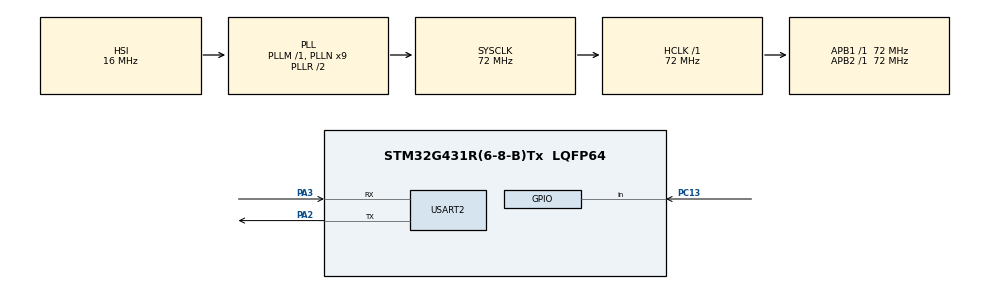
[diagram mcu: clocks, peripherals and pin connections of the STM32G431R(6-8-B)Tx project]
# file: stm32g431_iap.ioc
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IWDG.Prescaler=IWDG_PRESCALER_256
Mcu.Family=STM32G4
Mcu.Name=STM32G431R(6-8-B)Tx
Mcu.Package=LQFP64
NVIC.PriorityGroup=NVIC_PRIORITYGROUP_4
PA2.Mode=Asynchronous
PA2.Signal=USART2_TX
PA3.Mode=Asynchronous
PA3.Signal=USART2_RX
PC13.Signal=GPIO_Input
ProjectManager.HeapSize=0x400
ProjectManager.StackSize=0x800
ProjectManager.TargetToolchain=MDK-ARM V5
RCC.ADC12Freq_Value=72000000
RCC.AHBFreq_Value=72000000
RCC.APB1Freq_Value=72000000
RCC.APB1TimFreq_Value=72000000
RCC.APB2Freq_Value=72000000
RCC.APB2TimFreq_Value=72000000
RCC.CortexFreq_Value=72000000
RCC.EXTERNAL_CLOCK_VALUE=12288000
RCC.HCLKFreq_Value=72000000
RCC.HSE_VALUE=24000000
RCC.HSI48_VALUE=48000000
RCC.HSI_VALUE=16000000
RCC.LSE_VALUE=32768
RCC.PLLN=9
RCC.SYSCLKFreq_VALUE=72000000
RCC.SYSCLKSource=RCC_SYSCLKSOURCE_PLLCLK
RCC.USBFreq_Value=72000000
RCC.VCOOutputFreq_Value=144000000
USART2.Parity=PARITY_EVEN
USART2.VirtualMode-Asynchronous=VM_ASYNC
USART2.WordLength=WORDLENGTH_9B
VP_IWDG_VS_IWDG.Mode=IWDG_Activate
VP_SYS_VS_DBSignals.Mode=DisableDeadBatterySignals
board=custom

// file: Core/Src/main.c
/* USER CODE BEGIN Header */
/**
  ******************************************************************************
  * @file           : main.c
  * @brief          : Main program body
  ******************************************************************************
  * @attention
  *
  * <h2><center>&copy; Copyright (c) 2020 STMicroelectronics.
  * All rights reserved.</center></h2>
  *
  * This software component is licensed by ST under BSD 3-Clause license,
  * the "License"; You may not use this file except in compliance with the
  * License. You may obtain a copy of the License at:
  *                        opensource.org/licenses/BSD-3-Clause
  *
  ******************************************************************************
  */
/* USER CODE END Header */
#include "main.h"
#include "iwdg.h"
#include "usart.h"
#include "gpio.h"

/* USER CODE BEGIN Includes */
#include <stdbool.h>
#include "app_openbootloader.h"
/* USER CODE END Includes */

void SystemClock_Config(void);

/* USER CODE BEGIN 0 */
#define APPLICATION_ADDRESS   (0x08004000)
extern void OPENBL_FLASH_JumpToAddress(uint32_t Address);

static void Check_Going_Application(void)
{
  /* To Do jump application*/
	if(LL_GPIO_IsInputPinSet(GPIOC, LL_GPIO_PIN_13) == 0)
	{
		if (((*(__IO uint32_t *) APPLICATION_ADDRESS) & 0x2FFF8000) == 0x20000000)
    {
			OPENBL_FLASH_JumpToAddress(APPLICATION_ADDRESS);
		}
	}
}
/* USER CODE END 0 */

int main(void)
{

  /* MCU Configuration--------------------------------------------------------*/

  /* Reset of all peripherals, Initializes the Flash interface and the Systick. */
  HAL_Init();

  /* Configure the system clock */
  SystemClock_Config();

  /* Initialize all configured peripherals */
  MX_GPIO_Init();
  MX_IWDG_Init();
  MX_USART2_UART_Init();
  /* USER CODE BEGIN 2 */
	OpenBootloader_Init();
  Check_Going_Application();
  /* USER CODE END 2 */

  /* Infinite loop */
  /* USER CODE BEGIN WHILE */
  while (1)
  {
		OpenBootloader_ProtocolDetection();
    /* USER CODE END WHILE */

  }
}

void SystemClock_Config(void)
{
  RCC_OscInitTypeDef RCC_OscInitStruct = {0};
  RCC_ClkInitTypeDef RCC_ClkInitStruct = {0};
  RCC_PeriphCLKInitTypeDef PeriphClkInit = {0};

  /** Configure the main internal regulator output voltage
  */
  HAL_PWREx_ControlVoltageScaling(PWR_REGULATOR_VOLTAGE_SCALE1);
  /** Initializes the RCC Oscillators according to the specified parameters
  * in the RCC_OscInitTypeDef structure.
  */
  RCC_OscInitStruct.OscillatorType = RCC_OSCILLATORTYPE_HSI|RCC_OSCILLATORTYPE_LSI;
  RCC_OscInitStruct.HSIState = RCC_HSI_ON;
  RCC_OscInitStruct.HSICalibrationValue = RCC_HSICALIBRATION_DEFAULT;
  RCC_OscInitStruct.LSIState = RCC_LSI_ON;
  RCC_OscInitStruct.PLL.PLLState = RCC_PLL_ON;
  RCC_OscInitStruct.PLL.PLLSource = RCC_PLLSOURCE_HSI;
  RCC_OscInitStruct.PLL.PLLM = RCC_PLLM_DIV1;
  RCC_OscInitStruct.PLL.PLLN = 9;
  RCC_OscInitStruct.PLL.PLLP = RCC_PLLP_DIV2;
  RCC_OscInitStruct.PLL.PLLQ = RCC_PLLQ_DIV2;
  RCC_OscInitStruct.PLL.PLLR = RCC_PLLR_DIV2;
  if (HAL_RCC_OscConfig(&RCC_OscInitStruct) != HAL_OK)
  {
    Error_Handler();
  }
  /** Initializes the CPU, AHB and APB buses clocks
  */
  RCC_ClkInitStruct.ClockType = RCC_CLOCKTYPE_HCLK|RCC_CLOCKTYPE_SYSCLK
                              |RCC_CLOCKTYPE_PCLK1|RCC_CLOCKTYPE_PCLK2;
  RCC_ClkInitStruct.SYSCLKSource = RCC_SYSCLKSOURCE_PLLCLK;
  RCC_ClkInitStruct.AHBCLKDivider = RCC_SYSCLK_DIV1;
  RCC_ClkInitStruct.APB1CLKDivider = RCC_HCLK_DIV1;
  RCC_ClkInitStruct.APB2CLKDivider = RCC_HCLK_DIV1;

  if (HAL_RCC_ClockConfig(&RCC_ClkInitStruct, FLASH_LATENCY_2) != HAL_OK)
  {
    Error_Handler();
  }
  /** Initializes the peripherals clocks
  */
  PeriphClkInit.PeriphClockSelection = RCC_PERIPHCLK_USART2;
  PeriphClkInit.Usart2ClockSelection = RCC_USART2CLKSOURCE_PCLK1;
  if (HAL_RCCEx_PeriphCLKConfig(&PeriphClkInit) != HAL_OK)
  {
    Error_Handler();
  }
}

/* USER CODE BEGIN 4 */
void System_DeInit(void)
{
  HAL_RCC_DeInit();
}
/* USER CODE END 4 */

void Error_Handler(void)
{
}

/************************ (C) COPYRIGHT STMicroelectronics *****END OF FILE****/
